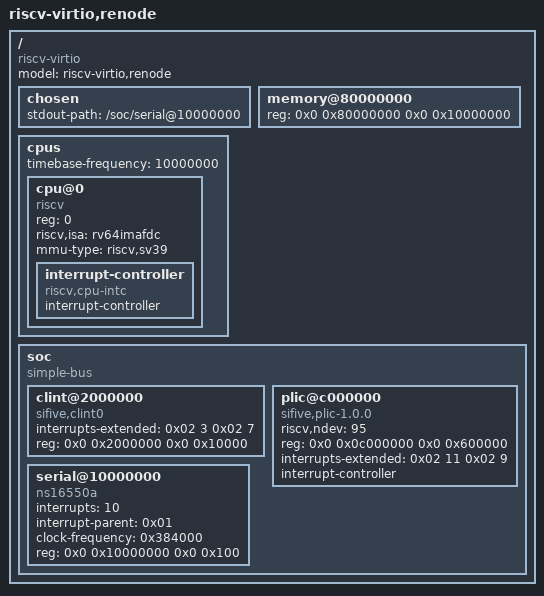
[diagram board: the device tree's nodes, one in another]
/dts-v1/;

/ {
    #address-cells = <2>;
    #size-cells = <2>;
    compatible = "riscv-virtio";
    model = "riscv-virtio,renode";

    chosen {
        stdout-path = "/soc/serial@10000000";
    };

    memory@80000000 {
        device_type = "memory";
        reg = <0x0 0x80000000 0x0 0x10000000>;
    };

    cpus {
        #address-cells = <1>;
        #size-cells = <0>;
        timebase-frequency = <10000000>;

        cpu@0 {
            device_type = "cpu";
            reg = <0>;
            status = "okay";
            compatible = "riscv";
            riscv,isa = "rv64imafdc";
            mmu-type = "riscv,sv39";

            interrupt-controller {
                #interrupt-cells = <1>;
                interrupt-controller;
                compatible = "riscv,cpu-intc";
                phandle = <2>;
            };
        };
    };

    soc {
        #address-cells = <2>;
        #size-cells = <2>;
        compatible = "simple-bus";
        ranges;

        clint@2000000 {
            interrupts-extended = <0x02 3 0x02 7>;
            reg = <0x0 0x2000000 0x0 0x10000>;
            compatible = "sifive,clint0", "riscv,clint0";
        };

        plic@c000000 {
            phandle = <1>;
            riscv,ndev = <95>;
            reg = <0x0 0x0c000000 0x0 0x600000>;
            interrupts-extended = <0x02 11 0x02 9>;
            interrupt-controller;
            compatible = "sifive,plic-1.0.0", "riscv,plic0";
            #address-cells = <0>;
            #interrupt-cells = <1>;
        };

        serial@10000000 {
            interrupts = <10>;
            interrupt-parent = <0x01>;
            clock-frequency = <0x384000>;
            reg = <0x0 0x10000000 0x0 0x100>;
            compatible = "ns16550a";
        };
    };
};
